# SMS_LITE_DMTIMER_0_SMS_LITE_TIFS_DMTIMER0_44133000h register map
Vendor: Texas Instruments
Peripheral module from a debugger description file (folder am62L).
Registers are 32-bit, read-write, reset 0x0 unless marked. A register's access mark holds for its fields unless they carry their own. Offsets are as the file gives them; lines under a group give offsets from that group; [hi:lo] are bit positions; {n}, {i} and the like mark numbered series; 'fields as' and 'values as' point back to an identical list; <NAME> marks a mode.

## SMS_LITE_TIFS_DMTIMER0
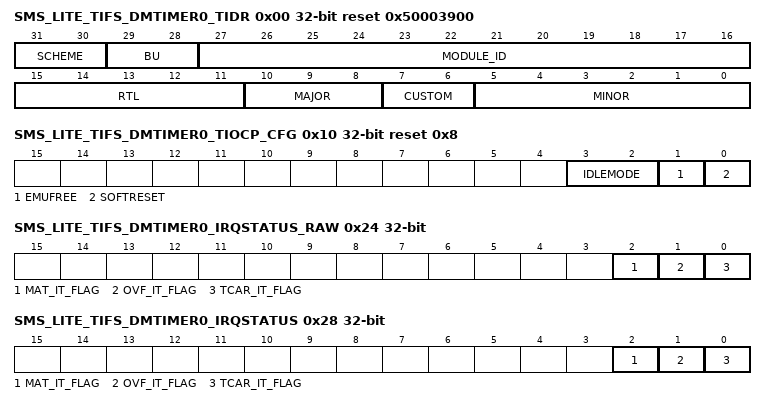
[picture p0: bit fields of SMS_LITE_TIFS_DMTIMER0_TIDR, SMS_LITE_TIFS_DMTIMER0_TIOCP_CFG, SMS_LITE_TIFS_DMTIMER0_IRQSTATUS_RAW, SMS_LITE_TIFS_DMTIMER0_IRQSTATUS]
0x00 SMS_LITE_TIFS_DMTIMER0_TIDR ro reset 0x50003900
  [31:30] SCHEME — PID register scheme Reset Source: sms_custom_rst_mod_g_rst_n
  [29:28] BU — Business Unit 1 Wireless BU2 Processors BU
  [27:16] MODULE_ID — Module ID Reset Source: sms_custom_rst_mod_g_rst_n
  [15:11] RTL — RTL revision. Will vary depending on release. Reset Source: sms_custom_rst_mod_g_rst_n
  [10:8] MAJOR — Major revision Reset Source: sms_custom_rst_mod_g_rst_n
  [7:6] CUSTOM — Custom Reset Source: sms_custom_rst_mod_g_rst_n
  [5:0] MINOR — Minor revision Reset Source: sms_custom_rst_mod_g_rst_n
0x10 SMS_LITE_TIFS_DMTIMER0_TIOCP_CFG reset 0x8 — This register controls the various parameters of the OCP interface
  [3:2] IDLEMODE — Idle Mode 0 local target's idle state follows (acknowledges) the system's idle reuquests unconditionaly, i.e. regardless of the IP module's internal requirments. Back mode, for debug only.1 local target never enteres idle state. Back mode, for debug only.2 local target's idle state eventually follows (acknowledges) the systems idle requests, depending on the IP modules internal requirments. IP module shall not generate (IRQ- or DMA-request-releated) wakuep events.3 local targets idle state eventually follows (acknowledges) the systems idle requests, depending on the IP module's internal requirents. IP module may generate (IRQ- or DMA-request-related) wakeup events when in idle state. Mode is only relevant if the appropriate IP module swakeup output(s) is (are) impolemented.
  [1] EMUFREE — Emulation Mode 0 The timer is frozen in emulation mode (PI_SUSPEND signal active)1 The timer runs free, regardless of PI_SUSPEND value
  [0] SOFTRESET — Software reset 0 Read: Reset Done, no pending action Write: no action1 Read: Reset ongoing Write: initiate software reset
0x20 SMS_LITE_TIFS_DMTIMER0_IRQ_EOI — Allows the generation of further pulses on the interrupt line, if an new interrupt event is pending, when using the pulsed output. Unused when using the level interrupt line
  [0] LINE_NUMBER — Idle Mode 0 End of interrupt
0x24 SMS_LITE_TIFS_DMTIMER0_IRQSTATUS_RAW access not given — Component interrupt request status.Check the corresponding secondary status register. Raw status is set even if event is not enabled. Write 1 to set the (raw) status, mostly for debug
  [2] MAT_IT_FLAG — Match Interrupt Reset Source: sms_custom_rst_mod_g_rst_n (access R/W1TS)
  [1] OVF_IT_FLAG — Overflow Interrupt Reset Source: sms_custom_rst_mod_g_rst_n (access R/W1TS)
  [0] TCAR_IT_FLAG — Capture Interrupt Reset Source: sms_custom_rst_mod_g_rst_n (access R/W1TS)
0x28 SMS_LITE_TIFS_DMTIMER0_IRQSTATUS access not given — Component interrupt request status.Check the corresponding secondary status register.Enabled status isn't set unless event is enabled.Write 1 to clear the status after interrupt has been serviced;raw status gets cleared, i.e. even if not enabled
  [2] MAT_IT_FLAG — Match Interrupt Reset Source: sms_custom_rst_mod_g_rst_n (access R/W1TC)
  [1] OVF_IT_FLAG — Overflow Interrupt Reset Source: sms_custom_rst_mod_g_rst_n (access R/W1TC)
  [0] TCAR_IT_FLAG — Capture Interrupt Reset Source: sms_custom_rst_mod_g_rst_n (access R/W1TC)
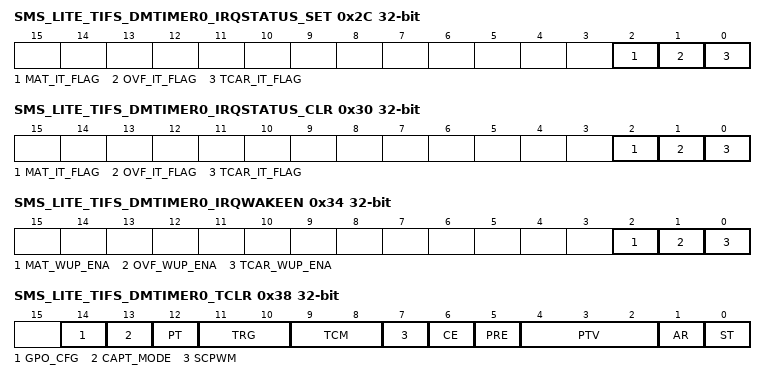
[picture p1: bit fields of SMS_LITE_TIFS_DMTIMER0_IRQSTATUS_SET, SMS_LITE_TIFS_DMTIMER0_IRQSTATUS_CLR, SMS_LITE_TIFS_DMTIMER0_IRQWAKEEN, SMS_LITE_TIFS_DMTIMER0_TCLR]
0x2C SMS_LITE_TIFS_DMTIMER0_IRQSTATUS_SET access not given — Component interrupt request enableWrite 1 to set, enable interrupt. Readout equal to corresponding _CLR register.
  fields as SMS_LITE_TIFS_DMTIMER0_IRQSTATUS_RAW
0x30 SMS_LITE_TIFS_DMTIMER0_IRQSTATUS_CLR access not given — Component interrupt request enable.Write 1 to clear, disable interrupt.Readout equal to corresponding _SET register
  fields as SMS_LITE_TIFS_DMTIMER0_IRQSTATUS
0x34 SMS_LITE_TIFS_DMTIMER0_IRQWAKEEN — Wakeup-enabled events taking place when module is idle shall generate an asynchronous wakeup
  [2] MAT_WUP_ENA — Match Wakeup Enable Reset Source: sms_custom_rst_mod_g_rst_n
  [1] OVF_WUP_ENA — Overflow Wakeup Enable Reset Source: sms_custom_rst_mod_g_rst_n
  [0] TCAR_WUP_ENA — Capture Wakeup Enable Reset Source: sms_custom_rst_mod_g_rst_n
0x38 SMS_LITE_TIFS_DMTIMER0_TCLR — This register controls optional features specific to the timer functionality
  [14] GPO_CFG — This field drives directly the PO_GPOCFG pin Reset Source: sms_custom_rst_mod_g_rst_n
  [13] CAPT_MODE — Capture mode select bit; First/second 0 Capture first enabled capture event in TCAR11 Capture first enabled capture event in TCAR2
  [12] PT — Pulse or Toggle select bit 0 Pulse modulation0 Toggle modulation
  [11:10] TRG — Trigger Output Mode 0 No Trigger1 Overflow Trigger2 Overflow and match Trigger
  [9:8] TCM — Transition Capture Mode 0 No capture1 Capture on rising edges of PI_EVNETCAPT2 Capture on falling edges of PI_EVENTCAPT3 Capture on both edges of PI_EVNENTCAPT
  [7] SCPWM — Pulse Width Modulation output pin default value Reset Source: sms_custom_rst_mod_g_rst_n
  [6] CE — Compare Enable 0 compare disabled1 compare enabled
  [5] PRE — Prescaler Enable 0 Prescaler disabeld1 Prescaler Enabled
  [4:2] PTV — Trigger Output Mode.The timer counter is prescaled with the value: 2^PTV Reset Source: sms_custom_rst_mod_g_rst_n
  [1] AR — Auto-reload mode 0 One shot mode overflow1 Auto-reload mode overflow
  [0] ST — Start/Stop timer control 0 Stop the timer1 Start the timer
0x3C SMS_LITE_TIFS_DMTIMER0_TCRR — This register holds the value of the internal counter
  [31:0] TIMER_COUNTER — Timer Counter Reset Source: sms_custom_rst_mod_g_rst_n
0x40 SMS_LITE_TIFS_DMTIMER0_TLDR — This register holds the timer's load value
  [31:0] LOAD_VALUE — Timer Counter Reset Source: sms_custom_rst_mod_g_rst_n
0x44 SMS_LITE_TIFS_DMTIMER0_TTGR — This register triggers a counter reload of timer by writing any value in it
  [31:0] TTRG_VLAUE — The value of the trigger register. During reads, it always return 0xFFFF_FFFF Reset Source: sms_custom_rst_mod_g_rst_n
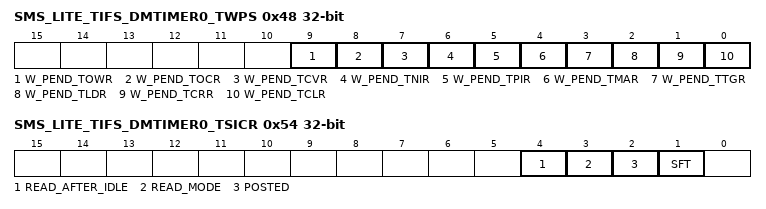
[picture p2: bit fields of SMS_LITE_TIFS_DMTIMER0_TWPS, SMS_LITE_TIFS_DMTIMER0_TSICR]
0x48 SMS_LITE_TIFS_DMTIMER0_TWPS ro — This register contains the write posting bits for all writ-able functional registers
  [9] W_PEND_TOWR — Write pending for register TOWR Reset Source: sms_custom_rst_mod_g_rst_n
  [8] W_PEND_TOCR — Write pending for register TOCR Reset Source: sms_custom_rst_mod_g_rst_n
  [7] W_PEND_TCVR — Write pending for register TCVR Reset Source: sms_custom_rst_mod_g_rst_n
  [6] W_PEND_TNIR — Write pending for register TNIR Reset Source: sms_custom_rst_mod_g_rst_n
  [5] W_PEND_TPIR — Write pending for register TPIR Reset Source: sms_custom_rst_mod_g_rst_n
  [4] W_PEND_TMAR — Write pending for register TMAR Reset Source: sms_custom_rst_mod_g_rst_n
  [3] W_PEND_TTGR — Write pending for register TTGR Reset Source: sms_custom_rst_mod_g_rst_n
  [2] W_PEND_TLDR — Write pending for register TLDR Reset Source: sms_custom_rst_mod_g_rst_n
  [1] W_PEND_TCRR — Write pending for register TCRR Reset Source: sms_custom_rst_mod_g_rst_n
  [0] W_PEND_TCLR — Write pending for register TCLR Reset Source: sms_custom_rst_mod_g_rst_n
0x4C SMS_LITE_TIFS_DMTIMER0_TMAR — This register holds the match value to be compared with the counter's value
  [31:0] COMPARE_VLAUE — The value of the match register Reset Source: sms_custom_rst_mod_g_rst_n
0x50 SMS_LITE_TIFS_DMTIMER0_TCAR1 ro — This register holds the value of the first counter register capture
  [31:0] CAPTURE_VALUE1 — The value of first captured counter register Reset Source: sms_custom_rst_mod_g_rst_n
0x54 SMS_LITE_TIFS_DMTIMER0_TSICR access per field — Timer Synchronous Interface Control Register
  [4] READ_AFTER_IDLE wo — Select if the synchronization mechanism used for first TCRR read operation after IDLE state is active 0 The synchronization mechanism is enabled1 The synchronization mechanism is disabled
  [3] READ_MODE wo — Select posted/non-posted mode for read operation.This bit is not used when configured in posted mode 0 When the module is configurated in non- posted mode the read operation is executed as posted read1 When the module is configured in non-posted mode the read operation is executed as read non-posted
  [2] POSTED rw — Reset value of POSTED depends on hardware integration module at design time.Software must read POSTED field to get the hardwar module configuration 0 Posted mode inactive: will delay the command accept output signal1 Posted mode active
  [1] SFT rw — This bit reset all the functional part of teh module 0 Software reset is disabled1 Software reset is enabled
0x58 SMS_LITE_TIFS_DMTIMER0_TCAR2 ro — This register holds the value of the second counter register capture
  [31:0] CAPTURE_VALUE2 — The value of second captured counter register Reset Source: sms_custom_rst_mod_g_rst_n
0x5C SMS_LITE_TIFS_DMTIMER0_TPIR — This register is used for 1ms tick generation.The TPIR register holds the value of the positive increment. The value of this register is added with the value of the TCVR to define whether next value loaded in TCRR will be the sub-period value or the over-period value
  [31:0] POSITIVE_INC_VALUE — The value of the positive increment Reset Source: sms_custom_rst_mod_g_rst_n
0x60 SMS_LITE_TIFS_DMTIMER0_TNIR — This register is used for 1ms tick generation. The TNIR register holds the value of the negative increment. The value of this register is added with the value of the TCVR to define whether next value loaded in TCRR will be the sub-period value or the over-period value
  [31:0] NEGATIVE_INC_VALUE — The value of the negative increment Reset Source: sms_custom_rst_mod_g_rst_n
0x64 SMS_LITE_TIFS_DMTIMER0_TCVR — This register is used for 1ms tick generation.The TCVR register defines whether next value loaded in TCRR will be the sub-period value or the over-period value
  [31:0] COUNTER_VALUE — The value of CVR counter Reset Source: sms_custom_rst_mod_g_rst_n
0x68 SMS_LITE_TIFS_DMTIMER0_TOCR — This register is used to mask the tick interrupt for a selected number of ticks
  [23:0] OVF_COUNTER_VALUE — The number of overflow events Reset Source: sms_custom_rst_mod_g_rst_n
0x6C SMS_LITE_TIFS_DMTIMER0_TOWR — This register holds the number of masked overflow interrupts
  [23:0] OVF_WRAPPING_VALUE — The number of masked interrupts Reset Source: sms_custom_rst_mod_g_rst_n
